# ESP32-H21 register map
Vendor: ESPRESSIF SYSTEMS (SHANGHAI) CO., LTD.; Series: ESP32 H-Series; File version: 1
CPU: RV32IMAC r0p0, little endian, no MPU, no FPU, 0 interrupt priority bits
Address unit: 32 bits
Registers are 32-bit, read-write, reset 0x0 unless marked. A register's access mark holds for its fields unless they carry their own. Offsets are from the block's base; [hi:lo] are bit positions; {n}, {i} and the like mark numbered series.

## CACHE (part 2 of 3) — CACHE Peripheral
Base 0x600C8000
0xD4 L1_ICACHE3_PRELOAD_ADDR ro — L1 instruction Cache 3 preload address configure register
  [31:0] L1_ICACHE3_PRELOAD_ADDR — Those bits are used to configure the start address of preload on L1-ICache3, which should be used together with L1_ICACHE3_PRELOAD_SIZE_REG
0xD8 L1_ICACHE3_PRELOAD_SIZE ro — L1 instruction Cache 3 preload size configure register
  [23:0] L1_ICACHE3_PRELOAD_SIZE — Those bits are used to configure the size of the first section of prelock on L1-ICache3, which should be used together with L1_ICACHE3_PRELOAD_ADDR_REG
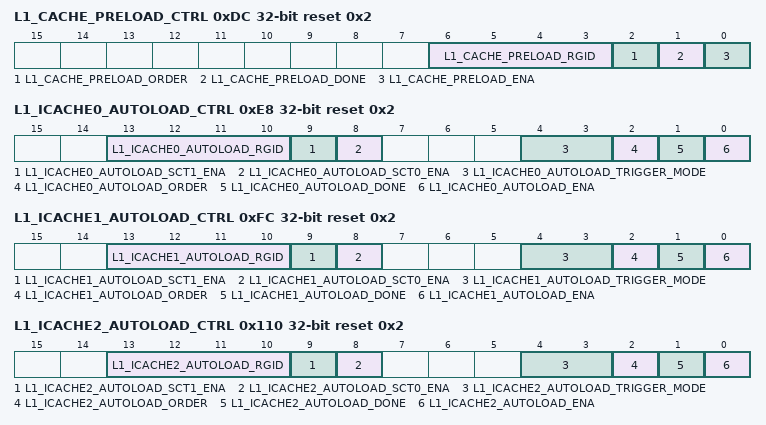
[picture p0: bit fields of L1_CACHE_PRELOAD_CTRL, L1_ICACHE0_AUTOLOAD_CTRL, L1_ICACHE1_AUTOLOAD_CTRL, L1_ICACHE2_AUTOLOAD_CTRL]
0xDC L1_CACHE_PRELOAD_CTRL access per field reset 0x2 — L1 cache preloading operation control register
  [6:3] L1_CACHE_PRELOAD_RGID rw — The bit is used to set the gid of l1 Cache preload.
  [2] L1_CACHE_PRELOAD_ORDER rw — Configures the direction of the preloading operation.\\ 0: Ascending\\ 1: Descending\\
  [1] L1_CACHE_PRELOAD_DONE ro — Represents whether the preloading operation is finished.\\ 0: Not finished\\ 1: Finished\\
  [0] L1_CACHE_PRELOAD_ENA rw — Configures whether to enable the preloading operation in the L1 cache. It will be cleared by hardware automatically after the preloading operation is done.\\ 0: Disable\\ 1: Enable\\
0xE0 L1_CACHE_PRELOAD_ADDR — L1 cache preloading address configuration register
  [31:0] L1_CACHE_PRELOAD_ADDR — Configures the starting virtual address for the preloading operation in the L1 cache. This field should be configured together with CACHE_L1_CACHE_PRELOAD_SIZE_REG.
0xE4 L1_CACHE_PRELOAD_SIZE — L1 cache preloading size configuration register
  [23:0] L1_CACHE_PRELOAD_SIZE — Configures the size of Section 0 for the preloading operation in the L1 cache. This field should be configured together with CACHE_L1_CACHE_PRELOAD_ADDR_REG.
0xE8 L1_ICACHE0_AUTOLOAD_CTRL access per field reset 0x2 — L1 instruction Cache 0 autoload-operation control register
  [13:10] L1_ICACHE0_AUTOLOAD_RGID rw — The bit is used to set the gid of l1 icache0 autoload.
  [9] L1_ICACHE0_AUTOLOAD_SCT1_ENA rw — The bit is used to enable the second section for autoload operation on L1-ICache0.
  [8] L1_ICACHE0_AUTOLOAD_SCT0_ENA rw — The bit is used to enable the first section for autoload operation on L1-ICache0.
  [4:3] L1_ICACHE0_AUTOLOAD_TRIGGER_MODE rw — The field is used to configure trigger mode of autoload operation on L1-ICache0. 0/3: miss-trigger, 1: hit-trigger, 2: miss-hit-trigger.
  [2] L1_ICACHE0_AUTOLOAD_ORDER rw — The bit is used to configure the direction of autoload operation on L1-ICache0. 0: ascending. 1: descending.
  [1] L1_ICACHE0_AUTOLOAD_DONE ro — The bit is used to indicate whether autoload operation on L1-ICache0 is finished or not. 0: not finished. 1: finished.
  [0] L1_ICACHE0_AUTOLOAD_ENA rw — The bit is used to enable and disable autoload operation on L1-ICache0. 1: enable, 0: disable.
0xEC L1_ICACHE0_AUTOLOAD_SCT0_ADDR — L1 instruction Cache 0 autoload section 0 address configure register
  [31:0] L1_ICACHE0_AUTOLOAD_SCT0_ADDR — Those bits are used to configure the start address of the first section for autoload operation on L1-ICache0. Note that it should be used together with L1_ICACHE0_AUTOLOAD_SCT0_SIZE and L1_ICACHE_AUTOLOAD_SCT0_ENA.
0xF0 L1_ICACHE0_AUTOLOAD_SCT0_SIZE — L1 instruction Cache 0 autoload section 0 size configure register
  [23:0] L1_ICACHE0_AUTOLOAD_SCT0_SIZE — Those bits are used to configure the size of the first section for autoload operation on L1-ICache0. Note that it should be used together with L1_ICACHE0_AUTOLOAD_SCT0_ADDR and L1_ICACHE_AUTOLOAD_SCT0_ENA.
0xF4 L1_ICACHE0_AUTOLOAD_SCT1_ADDR — L1 instruction Cache 0 autoload section 1 address configure register
  [31:0] L1_ICACHE0_AUTOLOAD_SCT1_ADDR — Those bits are used to configure the start address of the second section for autoload operation on L1-ICache0. Note that it should be used together with L1_ICACHE0_AUTOLOAD_SCT1_SIZE and L1_ICACHE_AUTOLOAD_SCT1_ENA.
0xF8 L1_ICACHE0_AUTOLOAD_SCT1_SIZE — L1 instruction Cache 0 autoload section 1 size configure register
  [23:0] L1_ICACHE0_AUTOLOAD_SCT1_SIZE — Those bits are used to configure the size of the second section for autoload operation on L1-ICache0. Note that it should be used together with L1_ICACHE0_AUTOLOAD_SCT1_ADDR and L1_ICACHE_AUTOLOAD_SCT1_ENA.
0xFC L1_ICACHE1_AUTOLOAD_CTRL access per field reset 0x2 — L1 instruction Cache 1 autoload-operation control register
  [13:10] L1_ICACHE1_AUTOLOAD_RGID rw — The bit is used to set the gid of l1 icache1 autoload.
  [9] L1_ICACHE1_AUTOLOAD_SCT1_ENA rw — The bit is used to enable the second section for autoload operation on L1-ICache1.
  [8] L1_ICACHE1_AUTOLOAD_SCT0_ENA rw — The bit is used to enable the first section for autoload operation on L1-ICache1.
  [4:3] L1_ICACHE1_AUTOLOAD_TRIGGER_MODE rw — The field is used to configure trigger mode of autoload operation on L1-ICache1. 0/3: miss-trigger, 1: hit-trigger, 2: miss-hit-trigger.
  [2] L1_ICACHE1_AUTOLOAD_ORDER rw — The bit is used to configure the direction of autoload operation on L1-ICache1. 0: ascending. 1: descending.
  [1] L1_ICACHE1_AUTOLOAD_DONE ro — The bit is used to indicate whether autoload operation on L1-ICache1 is finished or not. 0: not finished. 1: finished.
  [0] L1_ICACHE1_AUTOLOAD_ENA rw — The bit is used to enable and disable autoload operation on L1-ICache1. 1: enable, 0: disable.
0x100 L1_ICACHE1_AUTOLOAD_SCT0_ADDR — L1 instruction Cache 1 autoload section 0 address configure register
  [31:0] L1_ICACHE1_AUTOLOAD_SCT0_ADDR — Those bits are used to configure the start address of the first section for autoload operation on L1-ICache1. Note that it should be used together with L1_ICACHE1_AUTOLOAD_SCT0_SIZE and L1_ICACHE_AUTOLOAD_SCT0_ENA.
0x104 L1_ICACHE1_AUTOLOAD_SCT0_SIZE — L1 instruction Cache 1 autoload section 0 size configure register
  [23:0] L1_ICACHE1_AUTOLOAD_SCT0_SIZE — Those bits are used to configure the size of the first section for autoload operation on L1-ICache1. Note that it should be used together with L1_ICACHE1_AUTOLOAD_SCT0_ADDR and L1_ICACHE_AUTOLOAD_SCT0_ENA.
0x108 L1_ICACHE1_AUTOLOAD_SCT1_ADDR — L1 instruction Cache 1 autoload section 1 address configure register
  [31:0] L1_ICACHE1_AUTOLOAD_SCT1_ADDR — Those bits are used to configure the start address of the second section for autoload operation on L1-ICache1. Note that it should be used together with L1_ICACHE1_AUTOLOAD_SCT1_SIZE and L1_ICACHE_AUTOLOAD_SCT1_ENA.
0x10C L1_ICACHE1_AUTOLOAD_SCT1_SIZE — L1 instruction Cache 1 autoload section 1 size configure register
  [23:0] L1_ICACHE1_AUTOLOAD_SCT1_SIZE — Those bits are used to configure the size of the second section for autoload operation on L1-ICache1. Note that it should be used together with L1_ICACHE1_AUTOLOAD_SCT1_ADDR and L1_ICACHE_AUTOLOAD_SCT1_ENA.
0x110 L1_ICACHE2_AUTOLOAD_CTRL ro reset 0x2 — L1 instruction Cache 2 autoload-operation control register
  [13:10] L1_ICACHE2_AUTOLOAD_RGID — The bit is used to set the gid of l1 icache2 autoload.
  [9] L1_ICACHE2_AUTOLOAD_SCT1_ENA — The bit is used to enable the second section for autoload operation on L1-ICache2.
  [8] L1_ICACHE2_AUTOLOAD_SCT0_ENA — The bit is used to enable the first section for autoload operation on L1-ICache2.
  [4:3] L1_ICACHE2_AUTOLOAD_TRIGGER_MODE — The field is used to configure trigger mode of autoload operation on L1-ICache2. 0/3: miss-trigger, 1: hit-trigger, 2: miss-hit-trigger.
  [2] L1_ICACHE2_AUTOLOAD_ORDER — The bit is used to configure the direction of autoload operation on L1-ICache2. 0: ascending. 1: descending.
  [1] L1_ICACHE2_AUTOLOAD_DONE — The bit is used to indicate whether autoload operation on L1-ICache2 is finished or not. 0: not finished. 1: finished.
  [0] L1_ICACHE2_AUTOLOAD_ENA — The bit is used to enable and disable autoload operation on L1-ICache2. 1: enable, 0: disable.
0x114 L1_ICACHE2_AUTOLOAD_SCT0_ADDR ro — L1 instruction Cache 2 autoload section 0 address configure register
  [31:0] L1_ICACHE2_AUTOLOAD_SCT0_ADDR — Those bits are used to configure the start address of the first section for autoload operation on L1-ICache2. Note that it should be used together with L1_ICACHE2_AUTOLOAD_SCT0_SIZE and L1_ICACHE_AUTOLOAD_SCT0_ENA.
0x118 L1_ICACHE2_AUTOLOAD_SCT0_SIZE ro — L1 instruction Cache 2 autoload section 0 size configure register
  [23:0] L1_ICACHE2_AUTOLOAD_SCT0_SIZE — Those bits are used to configure the size of the first section for autoload operation on L1-ICache2. Note that it should be used together with L1_ICACHE2_AUTOLOAD_SCT0_ADDR and L1_ICACHE_AUTOLOAD_SCT0_ENA.
0x11C L1_ICACHE2_AUTOLOAD_SCT1_ADDR ro — L1 instruction Cache 2 autoload section 1 address configure register
  [31:0] L1_ICACHE2_AUTOLOAD_SCT1_ADDR — Those bits are used to configure the start address of the second section for autoload operation on L1-ICache2. Note that it should be used together with L1_ICACHE2_AUTOLOAD_SCT1_SIZE and L1_ICACHE_AUTOLOAD_SCT1_ENA.
0x120 L1_ICACHE2_AUTOLOAD_SCT1_SIZE ro — L1 instruction Cache 2 autoload section 1 size configure register
  [23:0] L1_ICACHE2_AUTOLOAD_SCT1_SIZE — Those bits are used to configure the size of the second section for autoload operation on L1-ICache2. Note that it should be used together with L1_ICACHE2_AUTOLOAD_SCT1_ADDR and L1_ICACHE_AUTOLOAD_SCT1_ENA.
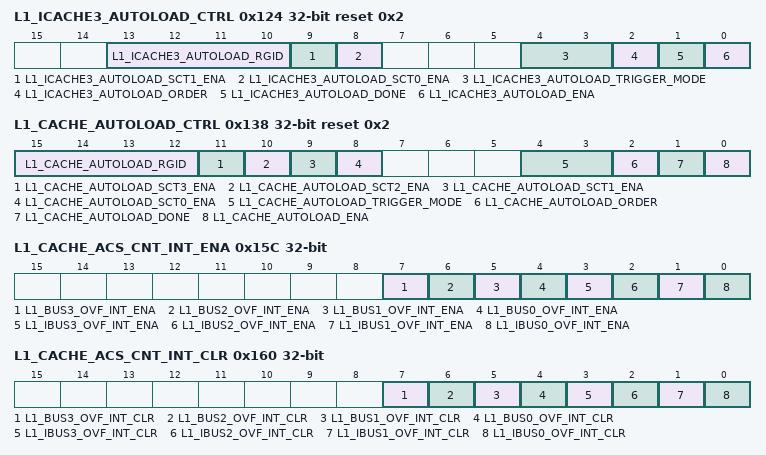
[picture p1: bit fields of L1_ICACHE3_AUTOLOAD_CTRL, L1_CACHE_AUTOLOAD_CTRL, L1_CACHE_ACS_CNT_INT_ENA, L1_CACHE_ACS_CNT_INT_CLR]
0x124 L1_ICACHE3_AUTOLOAD_CTRL ro reset 0x2 — L1 instruction Cache 3 autoload-operation control register
  [13:10] L1_ICACHE3_AUTOLOAD_RGID — The bit is used to set the gid of l1 icache3 autoload.
  [9] L1_ICACHE3_AUTOLOAD_SCT1_ENA — The bit is used to enable the second section for autoload operation on L1-ICache3.
  [8] L1_ICACHE3_AUTOLOAD_SCT0_ENA — The bit is used to enable the first section for autoload operation on L1-ICache3.
  [4:3] L1_ICACHE3_AUTOLOAD_TRIGGER_MODE — The field is used to configure trigger mode of autoload operation on L1-ICache3. 0/3: miss-trigger, 1: hit-trigger, 2: miss-hit-trigger.
  [2] L1_ICACHE3_AUTOLOAD_ORDER — The bit is used to configure the direction of autoload operation on L1-ICache3. 0: ascending. 1: descending.
  [1] L1_ICACHE3_AUTOLOAD_DONE — The bit is used to indicate whether autoload operation on L1-ICache3 is finished or not. 0: not finished. 1: finished.
  [0] L1_ICACHE3_AUTOLOAD_ENA — The bit is used to enable and disable autoload operation on L1-ICache3. 1: enable, 0: disable.
0x128 L1_ICACHE3_AUTOLOAD_SCT0_ADDR ro — L1 instruction Cache 3 autoload section 0 address configure register
  [31:0] L1_ICACHE3_AUTOLOAD_SCT0_ADDR — Those bits are used to configure the start address of the first section for autoload operation on L1-ICache3. Note that it should be used together with L1_ICACHE3_AUTOLOAD_SCT0_SIZE and L1_ICACHE_AUTOLOAD_SCT0_ENA.
0x12C L1_ICACHE3_AUTOLOAD_SCT0_SIZE ro — L1 instruction Cache 3 autoload section 0 size configure register
  [23:0] L1_ICACHE3_AUTOLOAD_SCT0_SIZE — Those bits are used to configure the size of the first section for autoload operation on L1-ICache3. Note that it should be used together with L1_ICACHE3_AUTOLOAD_SCT0_ADDR and L1_ICACHE_AUTOLOAD_SCT0_ENA.
0x130 L1_ICACHE3_AUTOLOAD_SCT1_ADDR ro — L1 instruction Cache 3 autoload section 1 address configure register
  [31:0] L1_ICACHE3_AUTOLOAD_SCT1_ADDR — Those bits are used to configure the start address of the second section for autoload operation on L1-ICache3. Note that it should be used together with L1_ICACHE3_AUTOLOAD_SCT1_SIZE and L1_ICACHE_AUTOLOAD_SCT1_ENA.
0x134 L1_ICACHE3_AUTOLOAD_SCT1_SIZE ro — L1 instruction Cache 3 autoload section 1 size configure register
  [23:0] L1_ICACHE3_AUTOLOAD_SCT1_SIZE — Reserved
0x138 L1_CACHE_AUTOLOAD_CTRL access per field reset 0x2 — L1 cache autoloading operation control register
  [15:12] L1_CACHE_AUTOLOAD_RGID rw — The bit is used to set the gid of l1 Cache autoload.
  [11] L1_CACHE_AUTOLOAD_SCT3_ENA rw — The bit is used to enable the fourth section for autoload operation on L1-Cache.
  [10] L1_CACHE_AUTOLOAD_SCT2_ENA rw — The bit is used to enable the third section for autoload operation on L1-Cache.
  [9] L1_CACHE_AUTOLOAD_SCT1_ENA rw — Configures whether to enable Section 1 for the autoloading operation in the L1 cache.\\ 0: Disable\\ 1: Enable\\
  [8] L1_CACHE_AUTOLOAD_SCT0_ENA rw — Configures whether to enable Section 0 for the autoloading operation in the L1 cache.\\ 0: Disable\\ 1: Enable\\
  [4:3] L1_CACHE_AUTOLOAD_TRIGGER_MODE rw — Configures the trigger mode of the autoloading operation in the L1 cache.\\ 0/3: Triggered by misses\\ 1: Triggered by hits\\ 2: Triggered by misses or hits\\
  [2] L1_CACHE_AUTOLOAD_ORDER rw — Configures the direction of the autoloading operation in the L1 cache.\\ 0: Ascending\\ 1: Descending\\
  [1] L1_CACHE_AUTOLOAD_DONE ro — Represents whether the autoloading operation in the L1 cache is finished.\\ 0: Not finished\\ 1: Finished\\
  [0] L1_CACHE_AUTOLOAD_ENA rw — Configures whether to enable the autoloading operation in the L1 cache.\\ 0: Disable\\ 1: Enable\\
0x13C L1_CACHE_AUTOLOAD_SCT0_ADDR — L1 cache autoloading Section 0 address configuration register
  [31:0] L1_CACHE_AUTOLOAD_SCT0_ADDR — Configures the starting virtual address of Section 0 for the autoloading operation in the L1 cache. Note that it should be used together with CACHE_L1_CACHE_AUTOLOAD_SCT0_SIZE and CACHE_L1_CACHE_AUTOLOAD_SCT0_ENA.
0x140 L1_CACHE_AUTOLOAD_SCT0_SIZE — L1 cache autoloading Section 0 size configuration register
  [23:0] L1_CACHE_AUTOLOAD_SCT0_SIZE — Configures the size of Section 0 for the autoloading operation in the L1 cache. Note that it should be used together with CACHE_L1_CACHE_AUTOLOAD_SCT0_ADDR and CACHE_L1_CACHE_AUTOLOAD_SCT0_ENA.
0x144 L1_CACHE_AUTOLOAD_SCT1_ADDR — L1 cache autoloading Section 1 address configuration register
  [31:0] L1_CACHE_AUTOLOAD_SCT1_ADDR — Configures the starting virtual address of Section 1 for the autoloading operation in the L1 cache. Note that it should be used together with CACHE_L1_CACHE_AUTOLOAD_SCT1_SIZE and CACHE_L1_CACHE_AUTOLOAD_SCT1_ENA.
0x148 L1_CACHE_AUTOLOAD_SCT1_SIZE — L1 cache autoloading Section 1 size configuration register
  [23:0] L1_CACHE_AUTOLOAD_SCT1_SIZE — Configures the size of Section 1 for the autoloading operation in the L1 cache. Note that it should be used together with CACHE_L1_CACHE_AUTOLOAD_SCT1_ADDR and CACHE_L1_CACHE_AUTOLOAD_SCT1_ENA.
0x14C L1_CACHE_AUTOLOAD_SCT2_ADDR — L1 data Cache autoload section 2 address configure register
  [31:0] L1_CACHE_AUTOLOAD_SCT2_ADDR — Those bits are used to configure the start address of the third section for autoload operation on L1-Cache. Note that it should be used together with L1_Cache_AUTOLOAD_SCT2_SIZE and L1_Cache_AUTOLOAD_SCT2_ENA.
0x150 L1_CACHE_AUTOLOAD_SCT2_SIZE — L1 data Cache autoload section 2 size configure register
  [23:0] L1_CACHE_AUTOLOAD_SCT2_SIZE — Those bits are used to configure the size of the third section for autoload operation on L1-Cache. Note that it should be used together with L1_Cache_AUTOLOAD_SCT2_ADDR and L1_Cache_AUTOLOAD_SCT2_ENA.
0x154 L1_CACHE_AUTOLOAD_SCT3_ADDR — L1 data Cache autoload section 1 address configure register
  [31:0] L1_CACHE_AUTOLOAD_SCT3_ADDR — Those bits are used to configure the start address of the fourth section for autoload operation on L1-Cache. Note that it should be used together with L1_Cache_AUTOLOAD_SCT3_SIZE and L1_Cache_AUTOLOAD_SCT3_ENA.
0x158 L1_CACHE_AUTOLOAD_SCT3_SIZE — L1 data Cache autoload section 1 size configure register
  [23:0] L1_CACHE_AUTOLOAD_SCT3_SIZE — Those bits are used to configure the size of the fourth section for autoload operation on L1-Cache. Note that it should be used together with L1_Cache_AUTOLOAD_SCT3_ADDR and L1_Cache_AUTOLOAD_SCT3_ENA.
0x15C L1_CACHE_ACS_CNT_INT_ENA access per field — Cache access counter interrupt enable register
  [7] L1_BUS3_OVF_INT_ENA ro — Reserved
  [6] L1_BUS2_OVF_INT_ENA ro — Reserved
  [5] L1_BUS1_OVF_INT_ENA rw — Write 1 to enable L1_BUS1_OVF_INT.
  [4] L1_BUS0_OVF_INT_ENA rw — Write 1 to enable L1_BUS0_OVF_INT.
  [3] L1_IBUS3_OVF_INT_ENA ro — Reserved
  [2] L1_IBUS2_OVF_INT_ENA ro — Reserved
  [1] L1_IBUS1_OVF_INT_ENA rw — The bit is used to enable interrupt of one of counters overflow that occurs in L1-ICache1 due to bus1 accesses L1-ICache1.
  [0] L1_IBUS0_OVF_INT_ENA rw — The bit is used to enable interrupt of one of counters overflow that occurs in L1-ICache0 due to bus0 accesses L1-ICache0.
0x160 L1_CACHE_ACS_CNT_INT_CLR wo — Cache access counter interrupt clear register
  [7] L1_BUS3_OVF_INT_CLR — Reserved
  [6] L1_BUS2_OVF_INT_CLR — Reserved
  [5] L1_BUS1_OVF_INT_CLR — Write 1 to clear L1_BUS1_OVF_INT.
  [4] L1_BUS0_OVF_INT_CLR — Write 1 to clear L1_BUS0_OVF_INT.
  [3] L1_IBUS3_OVF_INT_CLR — Reserved
  [2] L1_IBUS2_OVF_INT_CLR — Reserved
  [1] L1_IBUS1_OVF_INT_CLR — The bit is used to clear counters overflow interrupt and counters in L1-ICache1 due to bus1 accesses L1-ICache1.
  [0] L1_IBUS0_OVF_INT_CLR — The bit is used to clear counters overflow interrupt and counters in L1-ICache0 due to bus0 accesses L1-ICache0.
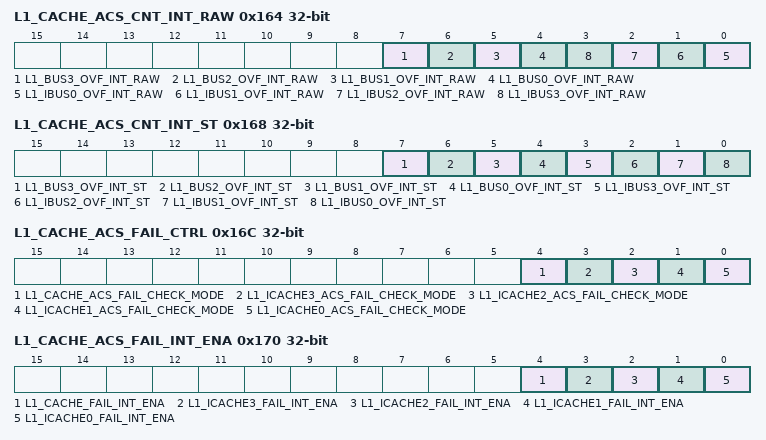
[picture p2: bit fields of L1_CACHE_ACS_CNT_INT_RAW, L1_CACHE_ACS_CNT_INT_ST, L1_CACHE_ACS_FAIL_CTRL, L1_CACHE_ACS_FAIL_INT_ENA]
0x164 L1_CACHE_ACS_CNT_INT_RAW — Cache access counter interrupt raw register
  [7] L1_BUS3_OVF_INT_RAW — The raw bit of the interrupt of one of counters overflow that occurs in L1-Cache due to bus3 accesses L1-Cache.
  [6] L1_BUS2_OVF_INT_RAW — The raw bit of the interrupt of one of counters overflow that occurs in L1-Cache due to bus2 accesses L1-Cache.
  [5] L1_BUS1_OVF_INT_RAW — The raw interrupt status of L1_BUS1_OVF_INT.
  [4] L1_BUS0_OVF_INT_RAW — The raw interrupt status of L1_BUS0_OVF_INT.
  [n] L1_IBUS{n}_OVF_INT_RAW (n=0..3) — The raw bit of the interrupt of one of counters overflow that occurs in L1-ICache{n} due to bus{n} accesses L1-ICache{n}.
0x168 L1_CACHE_ACS_CNT_INT_ST ro — Cache access counter interrupt status register
  [7] L1_BUS3_OVF_INT_ST — Reserved
  [6] L1_BUS2_OVF_INT_ST — Reserved
  [5] L1_BUS1_OVF_INT_ST — The masked interrupt status of L1_BUS1_OVF_INT.
  [4] L1_BUS0_OVF_INT_ST — The masked interrupt status of L1_BUS0_OVF_INT.
  [3] L1_IBUS3_OVF_INT_ST — Reserved
  [2] L1_IBUS2_OVF_INT_ST — Reserved
  [1] L1_IBUS1_OVF_INT_ST — The bit indicates the interrupt status of one of counters overflow that occurs in L1-ICache1 due to bus1 accesses L1-ICache1.
  [0] L1_IBUS0_OVF_INT_ST — The bit indicates the interrupt status of one of counters overflow that occurs in L1-ICache0 due to bus0 accesses L1-ICache0.
0x16C L1_CACHE_ACS_FAIL_CTRL access per field — Cache access failure mode configuration register
  [4] L1_CACHE_ACS_FAIL_CHECK_MODE rw — Configures whether to propagate the error that occurs during access to lower-level memory to higher-level access. \\ 0: Not propagate\\ 1: Propagate\\
  [3] L1_ICACHE3_ACS_FAIL_CHECK_MODE ro — The bit is used to configure l1 icache3 access fail check mode. 0: the access fail is not propagated to the request, 1: the access fail is propagated to the request
  [2] L1_ICACHE2_ACS_FAIL_CHECK_MODE ro — The bit is used to configure l1 icache2 access fail check mode. 0: the access fail is not propagated to the request, 1: the access fail is propagated to the request
  [1] L1_ICACHE1_ACS_FAIL_CHECK_MODE rw — The bit is used to configure l1 icache1 access fail check mode. 0: the access fail is not propagated to the request, 1: the access fail is propagated to the request
  [0] L1_ICACHE0_ACS_FAIL_CHECK_MODE rw — The bit is used to configure l1 icache0 access fail check mode. 0: the access fail is not propagated to the request, 1: the access fail is propagated to the request
0x170 L1_CACHE_ACS_FAIL_INT_ENA access per field — Cache access failed interrupt enable register
  [4] L1_CACHE_FAIL_INT_ENA rw — Write 1 to enable L1_CACHE_FAIL_INT.
  [3] L1_ICACHE3_FAIL_INT_ENA ro — Reserved
  [2] L1_ICACHE2_FAIL_INT_ENA ro — Reserved
  [1] L1_ICACHE1_FAIL_INT_ENA rw — The bit is used to enable interrupt of access fail that occurs in L1-ICache1 due to cpu accesses L1-ICache1.
  [0] L1_ICACHE0_FAIL_INT_ENA rw — The bit is used to enable interrupt of access fail that occurs in L1-ICache0 due to cpu accesses L1-ICache0.
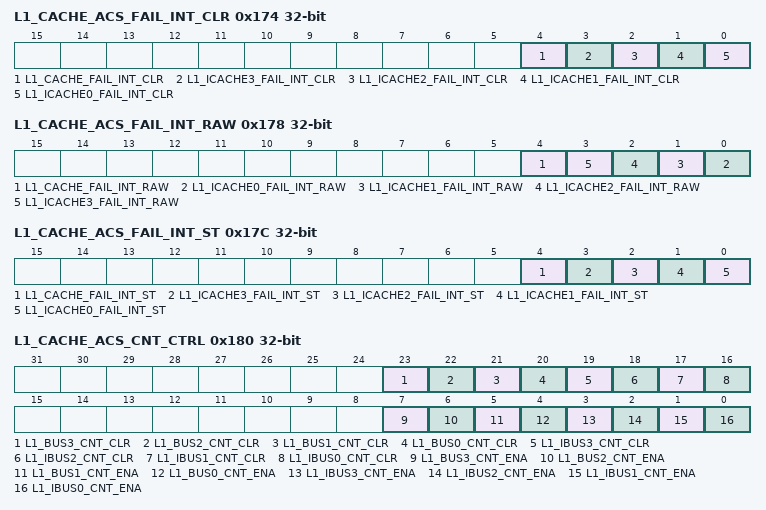
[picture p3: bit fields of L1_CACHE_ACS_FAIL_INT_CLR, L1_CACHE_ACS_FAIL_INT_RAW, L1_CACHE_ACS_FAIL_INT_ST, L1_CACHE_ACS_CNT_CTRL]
0x174 L1_CACHE_ACS_FAIL_INT_CLR wo — L1 cache access failed interrupt clear register
  [4] L1_CACHE_FAIL_INT_CLR — Write 1 to clear L1_CACHE_FAIL_INT.
  [3] L1_ICACHE3_FAIL_INT_CLR — Reserved
  [2] L1_ICACHE2_FAIL_INT_CLR — Reserved
  [1] L1_ICACHE1_FAIL_INT_CLR — The bit is used to clear interrupt of access fail that occurs in L1-ICache1 due to cpu accesses L1-ICache1.
  [0] L1_ICACHE0_FAIL_INT_CLR — The bit is used to clear interrupt of access fail that occurs in L1-ICache0 due to cpu accesses L1-ICache0.
0x178 L1_CACHE_ACS_FAIL_INT_RAW — Cache access failed interrupt raw register
  [4] L1_CACHE_FAIL_INT_RAW — The raw interrupt status of L1_CACHE_FAIL_INT.
  [n] L1_ICACHE{n}_FAIL_INT_RAW (n=0..3) — The raw bit of the interrupt of access fail that occurs in L1-ICache{n}.
0x17C L1_CACHE_ACS_FAIL_INT_ST ro — Cache access failed interrupt status register
  [4] L1_CACHE_FAIL_INT_ST — The masked interrupt status of L1_CACHE_FAIL_INT.
  [3] L1_ICACHE3_FAIL_INT_ST — Reserved
  [2] L1_ICACHE2_FAIL_INT_ST — Reserved
  [1] L1_ICACHE1_FAIL_INT_ST — The bit indicates the interrupt status of access fail that occurs in L1-ICache1 due to cpu accesses L1-ICache.
  [0] L1_ICACHE0_FAIL_INT_ST — The bit indicates the interrupt status of access fail that occurs in L1-ICache0 due to cpu accesses L1-ICache.
0x180 L1_CACHE_ACS_CNT_CTRL access per field — Cache access counter enable and clear register
  [23] L1_BUS3_CNT_CLR wo — Reserved
  [22] L1_BUS2_CNT_CLR wo — Reserved
  [21] L1_BUS1_CNT_CLR wo — Configures whether to clear the BUS1 counters in the L1 cache.\\ 0: Not clear\\ 1: Clear\\
  [20] L1_BUS0_CNT_CLR wo — Configures whether to clear the BUS0 counters in the L1 cache. \\ 0: Not clear\\ 1: Clear\\
  [19] L1_IBUS3_CNT_CLR wo — Reserved
  [18] L1_IBUS2_CNT_CLR wo — Reserved
  [17] L1_IBUS1_CNT_CLR wo — The bit is used to clear ibus1 counter in L1-ICache1.
  [16] L1_IBUS0_CNT_CLR wo — The bit is used to clear ibus0 counter in L1-ICache0.
  [7] L1_BUS3_CNT_ENA rw — Reserved
  [6] L1_BUS2_CNT_ENA rw — Reserved
  [5] L1_BUS1_CNT_ENA rw — Configures whether to enable the BUS1 counters in the L1 cache.\\ 0: Disable\\ 1: Enable\\
  [4] L1_BUS0_CNT_ENA rw — Configures whether to enable the BUS0 counters in the L1 cache.\\ 0: Disable\\ 1: Enable\\
  [3] L1_IBUS3_CNT_ENA rw — Reserved
  [2] L1_IBUS2_CNT_ENA rw — Reserved
  [1] L1_IBUS1_CNT_ENA rw — The bit is used to enable ibus1 counter in L1-ICache1.
  [0] L1_IBUS0_CNT_ENA rw — The bit is used to enable ibus0 counter in L1-ICache0.
{0x184+0x10*i} L1_IBUS{i}_ACS_HIT_CNT ro (i=0..3) — L1-ICache bus{i} Hit-Access Counter register
  [31:0] L1_IBUS{i}_HIT_CNT — The register records the number of hits when bus{i} accesses L1-ICache{i}.
{0x188+0x10*i} L1_IBUS{i}_ACS_MISS_CNT ro (i=0..3) — L1-ICache bus{i} Miss-Access Counter register
  [31:0] L1_IBUS{i}_MISS_CNT — The register records the number of missing when bus{i} accesses L1-ICache{i}.
{0x18C+0x10*i} L1_IBUS{i}_ACS_CONFLICT_CNT ro (i=0..3) — L1-ICache bus{i} Conflict-Access Counter register
  [31:0] L1_IBUS{i}_CONFLICT_CNT — The register records the number of access-conflicts when bus{i} accesses L1-ICache{i}.
{0x190+0x10*i} L1_IBUS{i}_ACS_NXTLVL_RD_CNT ro (i=0..3) — L1-ICache bus{i} Next-Level-Access Counter register
  [31:0] L1_IBUS{i}_NXTLVL_RD_CNT — The register records the number of times that L1-ICache accesses L2-Cache due to bus{i} accessing L1-ICache{i}.
0x1C4 L1_BUS0_ACS_HIT_CNT ro — L1 cache BUS1 hit-access counter register
  [31:0] L1_BUS0_HIT_CNT — Represents the number of hits when BUS0 accesses the L1 cache.
0x1C8 L1_BUS0_ACS_MISS_CNT ro — L1 cache BUS0 missed-access counter register
  [31:0] L1_BUS0_MISS_CNT — Represents the number of misses when BUS0 accesses the L1 cache.
0x1CC L1_BUS0_ACS_CONFLICT_CNT ro — L1 cache BUS0 conflicting-access counter register
  [31:0] L1_BUS0_CONFLICT_CNT — Represents the number of access conflicts when BUS0 accesses the L1 cache.
0x1D0 L1_BUS0_ACS_NXTLVL_RD_CNT ro — L1 cache BUS0 next-level-access counter register
  [31:0] L1_BUS0_NXTLVL_RD_CNT — Represents the number of times the L1 cache accesses the next-level module due to BUS0 access.
{0x1D4+0x14*i} L1_BUS{i}_ACS_NXTLVL_WR_CNT ro (i=0..2) — L1-Cache bus{i} WB-Access Counter register
  [31:0] L1_BUS{i}_NXTLVL_WR_CNT — The register records the number of write back when bus{i} accesses L1-Cache.
0x1D8 L1_BUS1_ACS_HIT_CNT ro — L1 cache BUS1 hit-access counter register
  [31:0] L1_BUS1_HIT_CNT — Represents the number of hits when BUS1 accesses the L1 cache.
0x1DC L1_BUS1_ACS_MISS_CNT ro — L1 cache BUS1 missed-access counter register
  [31:0] L1_BUS1_MISS_CNT — Represents the number of misses when BUS1 accesses the L1 cache.
0x1E0 L1_BUS1_ACS_CONFLICT_CNT ro — L1 cache BUS1 conflicting-access counter register
  [31:0] L1_BUS1_CONFLICT_CNT — Represents the number of access conflicts when BUS1 accesses the L1 cache.
0x1E4 L1_BUS1_ACS_NXTLVL_RD_CNT ro — L1 cache BUS1 next-level-access counter register
  [31:0] L1_BUS1_NXTLVL_RD_CNT — Indicates the number of times the L1 cache accesses the next-level module due to BUS1 access.
0x1EC L1_BUS2_ACS_HIT_CNT ro — L1-Cache bus2 Hit-Access Counter register
  [31:0] L1_BUS2_HIT_CNT — The register records the number of hits when bus2 accesses L1-Cache.
0x1F0 L1_BUS2_ACS_MISS_CNT ro — L1-Cache bus2 Miss-Access Counter register
  [31:0] L1_BUS2_MISS_CNT — The register records the number of missing when bus2 accesses L1-Cache.
0x1F4 L1_BUS2_ACS_CONFLICT_CNT ro — L1-Cache bus2 Conflict-Access Counter register
  [31:0] L1_BUS2_CONFLICT_CNT — The register records the number of access-conflicts when bus2 accesses L1-Cache.
0x1F8 L1_BUS2_ACS_NXTLVL_RD_CNT ro — L1-Cache bus2 Next-Level-Access Counter register
  [31:0] L1_BUS2_NXTLVL_RD_CNT — The register records the number of times that L1-Cache accesses L2-Cache due to bus2 accessing L1-Cache.
0x200 L1_BUS3_ACS_HIT_CNT ro — L1-Cache bus3 Hit-Access Counter register
  [31:0] L1_BUS3_HIT_CNT — The register records the number of hits when bus3 accesses L1-Cache.
0x204 L1_BUS3_ACS_MISS_CNT ro — L1-Cache bus3 Miss-Access Counter register
  [31:0] L1_BUS3_MISS_CNT — The register records the number of missing when bus3 accesses L1-Cache.
0x208 L1_BUS3_ACS_CONFLICT_CNT ro — L1-Cache bus3 Conflict-Access Counter register
  [31:0] L1_BUS3_CONFLICT_CNT — The register records the number of access-conflicts when bus3 accesses L1-Cache.
0x20C L1_BUS3_ACS_NXTLVL_RD_CNT ro — L1-Cache bus3 Next-Level-Access Counter register
  [31:0] L1_BUS3_NXTLVL_RD_CNT — The register records the number of times that L1-Cache accesses L2-Cache due to bus3 accessing L1-Cache.
0x210 L1_BUS3_ACS_NXTLVL_WR_CNT ro — L1-Cache bus3 WB-Access Counter register
  [31:0] L1_BUS3_NXTLVL_WR_CNT — The register records the number of write back when bus0 accesses L1-Cache.
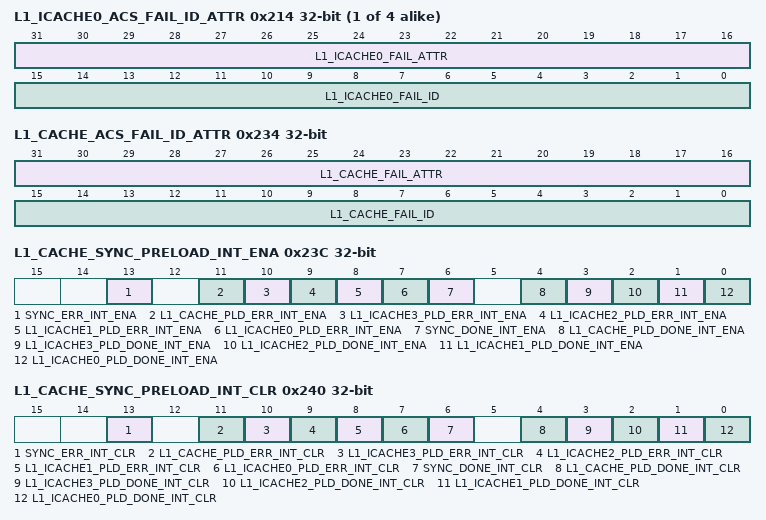
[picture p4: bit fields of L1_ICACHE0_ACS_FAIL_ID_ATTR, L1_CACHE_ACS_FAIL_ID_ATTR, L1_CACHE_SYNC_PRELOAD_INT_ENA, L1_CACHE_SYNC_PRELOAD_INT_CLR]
{0x214+8i} L1_ICACHE{i}_ACS_FAIL_ID_ATTR ro (i=0..3) — L1-ICache0 Access Fail ID/attribution information register
  [31:16] L1_ICACHE{i}_FAIL_ATTR — The register records the attribution of fail-access when cache{i} accesses L1-ICache.
  [15:0] L1_ICACHE{i}_FAIL_ID — The register records the ID of fail-access when cache{i} accesses L1-ICache.
{0x218+8i} L1_ICACHE{i}_ACS_FAIL_ADDR ro (i=0..3) — L1-ICache0 Access Fail Address information register
  [31:0] L1_ICACHE{i}_FAIL_ADDR — The register records the address of fail-access when cache{i} accesses L1-ICache.
0x234 L1_CACHE_ACS_FAIL_ID_ATTR ro — L1-Cache Access Fail ID/attribution information register
  [31:16] L1_CACHE_FAIL_ATTR — Represents the attribute of the failed access to the L1 cache.\\ Bit 0: Fetching instructions\\ Bit 1: Reading data\\ Bit 7: non-cacheable\\ Others: reserved\\
  [15:0] L1_CACHE_FAIL_ID — Represents the ID of the failed access to the L1 cache.\\ Bit 4: BUS0\\ Bit 5: BUS1\\ Others: reserved\\
0x238 L1_CACHE_ACS_FAIL_ADDR ro — L1 cache access failed address information register
  [31:0] L1_CACHE_FAIL_ADDR — Represents the address of the failed access to the L1 cache.
0x23C L1_CACHE_SYNC_PRELOAD_INT_ENA — Sync and preloading operation interrupt enable register
  [13] SYNC_ERR_INT_ENA — Write 1 to enable CACHE_SYNC_ERR_INT.
  [11] L1_CACHE_PLD_ERR_INT_ENA — Write 1 to enable CACHE_PLD_ERR_INT.
  [10] L1_ICACHE3_PLD_ERR_INT_ENA — Reserved
  [9] L1_ICACHE2_PLD_ERR_INT_ENA — Reserved
  [8] L1_ICACHE1_PLD_ERR_INT_ENA — The bit is used to enable interrupt of L1-ICache1 preload-operation error.
  [7] L1_ICACHE0_PLD_ERR_INT_ENA — The bit is used to enable interrupt of L1-ICache0 preload-operation error.
  [6] SYNC_DONE_INT_ENA — Write 1 to enable CACHE_SYNC_DONE_INT.
  [4] L1_CACHE_PLD_DONE_INT_ENA — Write 1 to enable L1_CACHE_PLD_DONE_INT.
  [3] L1_ICACHE3_PLD_DONE_INT_ENA — Reserved
  [2] L1_ICACHE2_PLD_DONE_INT_ENA — Reserved
  [1] L1_ICACHE1_PLD_DONE_INT_ENA — The bit is used to enable interrupt of L1-ICache1 preload-operation. If preload operation is done, interrupt occurs.
  [0] L1_ICACHE0_PLD_DONE_INT_ENA — The bit is used to enable interrupt of L1-ICache0 preload-operation. If preload operation is done, interrupt occurs.
0x240 L1_CACHE_SYNC_PRELOAD_INT_CLR wo — Sync and preloading operation interrupt clear register
  [13] SYNC_ERR_INT_CLR — Write 1 to clear CACHE_SYNC_ERR_INT.
  [11] L1_CACHE_PLD_ERR_INT_CLR — Write 1 to clear L1_CACHE_PLD_ERR_INT.
  [10] L1_ICACHE3_PLD_ERR_INT_CLR — Reserved
  [9] L1_ICACHE2_PLD_ERR_INT_CLR — Reserved
  [8] L1_ICACHE1_PLD_ERR_INT_CLR — The bit is used to clear interrupt of L1-ICache1 preload-operation error.
  [7] L1_ICACHE0_PLD_ERR_INT_CLR — The bit is used to clear interrupt of L1-ICache0 preload-operation error.
  [6] SYNC_DONE_INT_CLR — Write 1 to clear CACHE_SYNC_DONE_INT.
  [4] L1_CACHE_PLD_DONE_INT_CLR — Write 1 to clear L1_CACHE_PLD_DONE_INT.
  [3] L1_ICACHE3_PLD_DONE_INT_CLR — Reserved
  [2] L1_ICACHE2_PLD_DONE_INT_CLR — Reserved
  [1] L1_ICACHE1_PLD_DONE_INT_CLR — The bit is used to clear interrupt that occurs only when L1-ICache1 preload-operation is done.
  [0] L1_ICACHE0_PLD_DONE_INT_CLR — The bit is used to clear interrupt that occurs only when L1-ICache0 preload-operation is done.
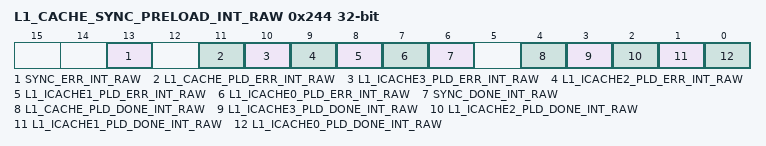
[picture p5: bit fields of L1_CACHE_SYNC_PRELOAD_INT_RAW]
0x244 L1_CACHE_SYNC_PRELOAD_INT_RAW — Sync and preloading operation interrupt raw register
  [13] SYNC_ERR_INT_RAW — The raw interrupt status of CACHE_SYNC_ERR_INT.
  [11] L1_CACHE_PLD_ERR_INT_RAW — The raw interrupt status of L1_CACHE_PLD_ERR_INT.
  [10] L1_ICACHE3_PLD_ERR_INT_RAW — Reserved
  [9] L1_ICACHE2_PLD_ERR_INT_RAW — Reserved
  [8] L1_ICACHE1_PLD_ERR_INT_RAW — The raw bit of the interrupt that occurs only when L1-ICache1 preload-operation error occurs.
  [7] L1_ICACHE0_PLD_ERR_INT_RAW — The raw bit of the interrupt that occurs only when L1-ICache0 preload-operation error occurs.
  [6] SYNC_DONE_INT_RAW — The raw interrupt status of CACHE_SYNC_DONE_INT.
  [4] L1_CACHE_PLD_DONE_INT_RAW — The raw interrupt status of L1_CACHE_PLD_DONE_INT.
  [3] L1_ICACHE3_PLD_DONE_INT_RAW — Reserved
  [2] L1_ICACHE2_PLD_DONE_INT_RAW — Reserved
  [1] L1_ICACHE1_PLD_DONE_INT_RAW — The raw bit of the interrupt that occurs only when L1-ICache1 preload-operation is done.
  [0] L1_ICACHE0_PLD_DONE_INT_RAW — The raw bit of the interrupt that occurs only when L1-ICache0 preload-operation is done.
